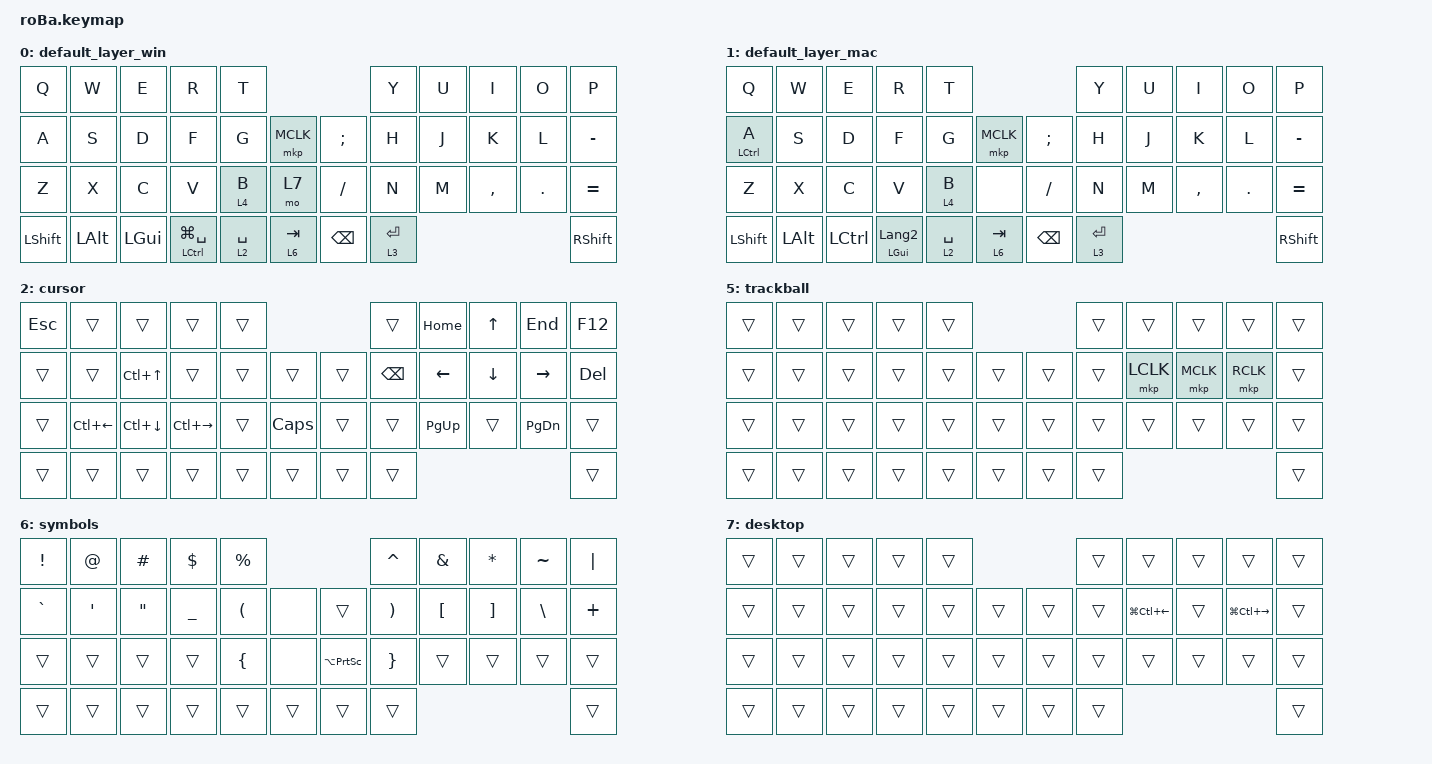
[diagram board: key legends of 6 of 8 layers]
#include <input/processors.dtsi>

#define ZMK_POINTING_DEFAULT_SCRL_VAL 80

#include <behaviors.dtsi>
#include <dt-bindings/zmk/bt.h>
#include <dt-bindings/zmk/keys.h>
#include <dt-bindings/zmk/outputs.h>
#include <dt-bindings/zmk/pointing.h>

&mt {
    flavor = "balanced";
    quick-tap-ms = <0>;
};

&trackball {
    automouse-layer = <5>;
    scroll-layers = <2>;

    // arrows {
    // layers = <3>;
    // bindings =
    // <&kp RIGHT_ARROW>,
    // <&kp LEFT_ARROW>,
    // <&kp UP_ARROW>,
    // <&kp DOWN_ARROW>;
    // tick = <10>;
    // wait-ms = <5>;
    // tap-ms = <5>;
    // };
};

&mkp_input_listener { input-processors = <&zip_temp_layer 5 250>; };

/ {
    combos {
        compatible = "zmk,combos";

        q_w_q {
            bindings = <&kp Q>;
            key-positions = <0 1>;
        };
    };

    behaviors {
        encoder_msc_up_down: encoder_msc_up_down {
            compatible = "zmk,behavior-sensor-rotate";
            label = "ENCODER_MSC_UP_DOWN";
            #sensor-binding-cells = <0>;
            bindings = <&msc SCRL_UP>, <&msc SCRL_DOWN>;

            tap-ms = <20>;
        };

        encoder_msc_down_up: encoder_msc_down_up {
            compatible = "zmk,behavior-sensor-rotate";
            label = "ENCODER_MSC_DOWN_UP";
            #sensor-binding-cells = <0>;
            bindings = <&msc SCRL_DOWN>, <&msc SCRL_UP>;

            tap-ms = <20>;
        };
    };

    macros {
        mac_setup: osx_setup {
            compatible = "zmk,behavior-macro";
            #binding-cells = <0>;
            bindings = <&bt BT_SEL 0 &to 1>;
            label = "OSX_SETUP";
        };

        win_setup: win_setup {
            compatible = "zmk,behavior-macro";
            #binding-cells = <0>;
            bindings = <&bt BT_SEL 1 &to 0>;
            label = "WIN_SETUP";
        };
    };

    keymap {
        compatible = "zmk,keymap";

        default_layer_win {
            bindings = <
&kp Q           &kp W         &kp E         &kp R                        &kp T                                      &kp Y        &kp U  &kp I      &kp O    &kp P
&kp A           &kp S         &kp D         &kp F                        &kp G        &mkp MCLK      &kp SEMICOLON  &kp H        &kp J  &kp K      &kp L    &kp MINUS
&kp Z           &kp X         &kp C         &kp V                        &lt 4 B      &mo 7          &kp SLASH      &kp N        &kp M  &kp COMMA  &kp DOT  &kp EQUAL
&kp LEFT_SHIFT  &kp LEFT_ALT  &kp LEFT_GUI  &mt LEFT_CONTROL LG(SPACE)  &lt 2 SPACE  &lt 6 TAB      &kp BACKSPACE  &lt 3 ENTER                             &kp RIGHT_SHIFT
            >;

            sensor-bindings = <&encoder_msc_down_up>;
        };

        default_layer_mac {
            bindings = <
&kp Q           &kp W         &kp E             &kp R                    &kp T                                      &kp Y        &kp U  &kp I      &kp O    &kp P
&mt LCTRL A     &kp S         &kp D             &kp F                    &kp G        &mkp MCLK      &kp SEMICOLON  &kp H        &kp J  &kp K      &kp L    &kp MINUS
&kp Z           &kp X         &kp C             &kp V                    &lt 4 B      &none          &kp SLASH      &kp N        &kp M  &kp COMMA  &kp DOT  &kp EQUAL
&kp LEFT_SHIFT  &kp LEFT_ALT  &kp LEFT_CONTROL  &mt LEFT_GUI LANGUAGE_2  &lt 2 SPACE  &lt 6 TAB      &kp BACKSPACE  &lt 3 ENTER                             &kp RIGHT_SHIFT
            >;

            sensor-bindings = <&encoder_msc_down_up>;
        };

        cursor {
            bindings = <
&kp ESCAPE  &trans              &trans            &trans         &trans                            &trans         &kp HOME     &kp UP    &kp END        &kp F12
&trans      &trans              &kp LC(UP_ARROW)  &trans         &trans  &trans            &trans  &kp BACKSPACE  &kp LEFT     &kp DOWN  &kp RIGHT      &kp DELETE
&trans      &kp LC(LEFT_ARROW)  &kp LC(DOWN)      &kp LC(RIGHT)  &trans  &kp CAPSLOCK      &trans  &trans         &kp PAGE_UP  &trans    &kp PAGE_DOWN  &trans
&trans      &trans              &trans            &trans         &trans  &trans            &trans  &trans                                               &trans
            >;

            sensor-bindings = <&encoder_msc_up_down>;
        };

        number {
            bindings = <
&trans        &trans        &trans        &trans          &trans                        &trans        &none   &none   &none   &none
&kp NUMBER_1  &kp NUMBER_2  &kp NUMBER_3  &kp NUMBER_4    &kp N5  &none        &trans   &kp NUMBER_6  &kp N7  &kp N8  &kp N9  &kp N0
&kp F1        &kp F2        &kp F3        &kp F4          &kp F5  &kp F11      &kp F12  &kp F6        &kp F7  &kp F8  &kp F9  &kp F10
&trans        &trans        &trans        &kp LANGUAGE_1  &trans  &trans       &trans   &trans
            >;
        };

        bluetooth {
            bindings = <
&trans  &trans  &trans  &trans  &trans                                   &bt BT_SEL 0  &bt BT_SEL 1  &bt BT_SEL 2  &bt BT_SEL 3  &bt BT_SEL 4
&trans  &trans  &trans  &trans  &trans  &trans           &trans          &mac_setup    &win_setup    &out OUT_USB  &out OUT_BLE  &out OUT_TOG
&trans  &trans  &trans  &trans  &trans  &bootloader      &trans          &trans        &trans        &bt BT_CLR    &trans        &trans
&trans  &trans  &trans  &trans  &trans  &trans           &bt BT_CLR_ALL
            >;
        };

        trackball {
            bindings = <
&trans  &trans  &trans  &trans  &trans                      &trans  &trans     &trans     &trans     &trans
&trans  &trans  &trans  &trans  &trans  &trans      &trans  &trans  &mkp LCLK  &mkp MCLK  &mkp RCLK  &trans
&trans  &trans  &trans  &trans  &trans  &trans      &trans  &trans  &trans     &trans     &trans     &trans
&trans  &trans  &trans  &trans  &trans  &trans      &trans  &trans                                   &trans
            >;
        };

        symbols {
            bindings = <
&kp EXCL   &kp AT   &kp HASH  &kp DOLLAR  &kp PERCENT                               &kp CARET              &kp AMPERSAND     &kp ASTERISK       &kp TILDE      &kp PIPE
&kp GRAVE  &kp SQT  &kp DQT   &kp UNDER   &kp LEFT_PARENTHESIS  &none       &trans  &kp RIGHT_PARENTHESIS  &kp LEFT_BRACKET  &kp RIGHT_BRACKET  &kp BACKSLASH  &kp PLUS
&trans     &trans   &trans    &trans      &kp LEFT_BRACE        &none       &kp LA(PSCRN)  &kp RIGHT_BRACE        &trans            &trans             &trans         &trans
&trans     &trans   &trans    &trans      &trans                &trans      &trans  &trans                                                                     &trans
            >;
        };

        desktop {
            bindings = <
&trans  &trans  &trans  &trans  &trans                      &trans  &trans             &trans  &trans              &trans
&trans  &trans  &trans  &trans  &trans  &trans      &trans  &trans  &kp LG(LC(LEFT))   &trans  &kp LG(LC(RIGHT))   &trans
&trans  &trans  &trans  &trans  &trans  &trans      &trans  &trans  &trans             &trans  &trans              &trans
&trans  &trans  &trans  &trans  &trans  &trans      &trans  &trans                                                 &trans
            >;
        };
    };
};
